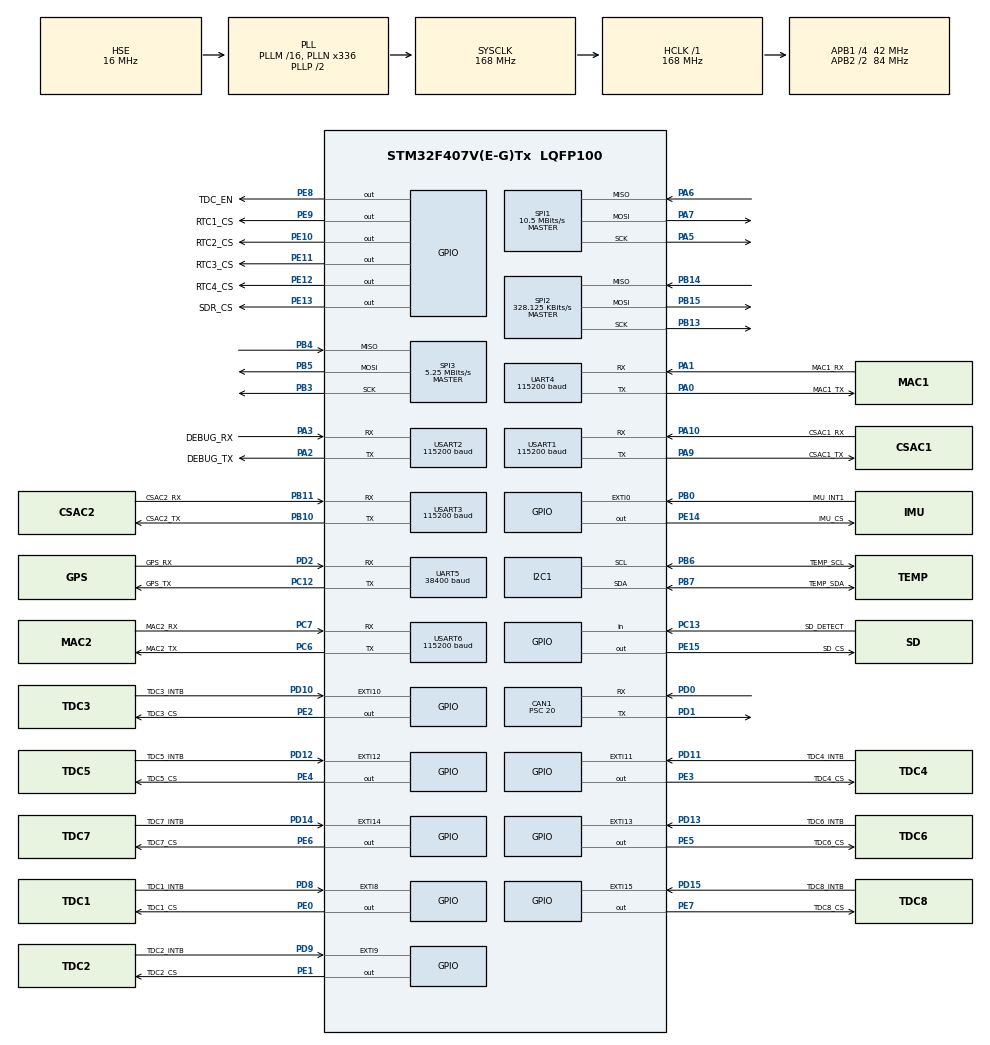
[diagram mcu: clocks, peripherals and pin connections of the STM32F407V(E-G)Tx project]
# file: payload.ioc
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CAN1.BS1=CAN_BS1_12TQ
CAN1.BS2=CAN_BS2_8TQ
CAN1.CalculateBaudRate=100000
CAN1.CalculateTimeBit=10000
CAN1.CalculateTimeQuantum=476.1904761904762
CAN1.Prescaler=20
CAN1.SJW=CAN_SJW_1TQ
Mcu.Family=STM32F4
Mcu.Name=STM32F407V(E-G)Tx
Mcu.Package=LQFP100
NVIC.EXTI0_IRQn=true\:0\:0\:false\:false\:true\:true\:true\:true
NVIC.EXTI15_10_IRQn=true\:0\:0\:false\:false\:true\:true\:true\:true
NVIC.EXTI9_5_IRQn=true\:0\:0\:false\:false\:true\:true\:true\:true
NVIC.PriorityGroup=NVIC_PRIORITYGROUP_4
PA0-WKUP.GPIO_Label=MAC1_TX
PA0-WKUP.Mode=Asynchronous
PA0-WKUP.Signal=UART4_TX
PA1.GPIO_Label=MAC1_RX
PA1.Mode=Asynchronous
PA1.Signal=UART4_RX
PA10.GPIO_Label=CSAC1_RX
PA10.Mode=Asynchronous
PA10.Signal=USART1_RX
PA13.Mode=Serial_Wire
PA13.Signal=SYS_JTMS-SWDIO
PA14.Mode=Serial_Wire
PA14.Signal=SYS_JTCK-SWCLK
PA2.GPIO_Label=DEBUG_TX
PA2.Mode=Asynchronous
PA2.Signal=USART2_TX
PA3.GPIO_Label=DEBUG_RX
PA3.Mode=Asynchronous
PA3.Signal=USART2_RX
PA5.Mode=Full_Duplex_Master
PA5.Signal=SPI1_SCK
PA6.Mode=Full_Duplex_Master
PA6.Signal=SPI1_MISO
PA7.Mode=Full_Duplex_Master
PA7.Signal=SPI1_MOSI
PA9.GPIO_Label=CSAC1_TX
PA9.Mode=Asynchronous
PA9.Signal=USART1_TX
PB0.GPIO_Label=IMU_INT1
PB0.GPIO_ModeDefaultEXTI=GPIO_MODE_IT_RISING
PB0.Signal=GPXTI0
PB10.GPIO_Label=CSAC2_TX
PB10.Mode=Asynchronous
PB10.Signal=USART3_TX
PB11.GPIO_Label=CSAC2_RX
PB11.Mode=Asynchronous
PB11.Signal=USART3_RX
PB13.Mode=Full_Duplex_Master
PB13.Signal=SPI2_SCK
PB14.Mode=Full_Duplex_Master
PB14.Signal=SPI2_MISO
PB15.Mode=Full_Duplex_Master
PB15.Signal=SPI2_MOSI
PB3.Mode=Full_Duplex_Master
PB3.Signal=SPI3_SCK
PB4.Mode=Full_Duplex_Master
PB4.Signal=SPI3_MISO
PB5.Mode=Full_Duplex_Master
PB5.Signal=SPI3_MOSI
PB6.GPIO_Label=TEMP_SCL
PB6.Mode=I2C
PB6.Signal=I2C1_SCL
PB7.GPIO_Label=TEMP_SDA
PB7.Mode=I2C
PB7.Signal=I2C1_SDA
PC12.GPIO_Label=GPS_TX
PC12.Mode=Asynchronous
PC12.Signal=UART5_TX
PC13-ANTI_TAMP.GPIO_Label=SD_DETECT
PC13-ANTI_TAMP.Signal=GPIO_Input
PC6.GPIO_Label=MAC2_TX
PC6.Mode=Asynchronous
PC6.Signal=USART6_TX
PC7.GPIO_Label=MAC2_RX
PC7.Mode=Asynchronous
PC7.Signal=USART6_RX
PD0.Mode=CAN_Activate
PD0.Signal=CAN1_RX
PD1.Mode=CAN_Activate
PD1.Signal=CAN1_TX
PD10.GPIO_Label=TDC3_INTB
PD10.GPIO_ModeDefaultEXTI=GPIO_MODE_IT_FALLING
PD10.Signal=GPXTI10
PD11.GPIO_Label=TDC4_INTB
PD11.GPIO_ModeDefaultEXTI=GPIO_MODE_IT_FALLING
PD11.Signal=GPXTI11
PD12.GPIO_Label=TDC5_INTB
PD12.GPIO_ModeDefaultEXTI=GPIO_MODE_IT_FALLING
PD12.Signal=GPXTI12
PD13.GPIO_Label=TDC6_INTB
PD13.GPIO_ModeDefaultEXTI=GPIO_MODE_IT_FALLING
PD13.Signal=GPXTI13
PD14.GPIO_Label=TDC7_INTB
PD14.GPIO_ModeDefaultEXTI=GPIO_MODE_IT_FALLING
PD14.Signal=GPXTI14
PD15.GPIO_Label=TDC8_INTB
PD15.GPIO_ModeDefaultEXTI=GPIO_MODE_IT_FALLING
PD15.Signal=GPXTI15
PD2.GPIO_Label=GPS_RX
PD2.Mode=Asynchronous
PD2.Signal=UART5_RX
PD8.GPIO_Label=TDC1_INTB
PD8.GPIO_ModeDefaultEXTI=GPIO_MODE_IT_FALLING
PD8.Signal=GPXTI8
PD9.GPIO_Label=TDC2_INTB
PD9.GPIO_ModeDefaultEXTI=GPIO_MODE_IT_FALLING
PD9.Signal=GPXTI9
PE0.GPIO_Label=TDC1_CS
PE0.PinState=GPIO_PIN_SET
PE0.Signal=GPIO_Output
PE1.GPIO_Label=TDC2_CS
PE1.PinState=GPIO_PIN_SET
PE1.Signal=GPIO_Output
PE10.GPIO_Label=RTC2_CS
PE10.PinState=GPIO_PIN_SET
PE10.Signal=GPIO_Output
PE11.GPIO_Label=RTC3_CS
PE11.PinState=GPIO_PIN_SET
PE11.Signal=GPIO_Output
PE12.GPIO_Label=RTC4_CS
PE12.PinState=GPIO_PIN_SET
PE12.Signal=GPIO_Output
PE13.GPIO_Label=SDR_CS
PE13.PinState=GPIO_PIN_SET
PE13.Signal=GPIO_Output
PE14.GPIO_Label=IMU_CS
PE14.PinState=GPIO_PIN_SET
PE14.Signal=GPIO_Output
PE15.GPIO_Label=SD_CS
PE15.PinState=GPIO_PIN_SET
PE15.Signal=GPIO_Output
PE2.GPIO_Label=TDC3_CS
PE2.PinState=GPIO_PIN_SET
PE2.Signal=GPIO_Output
PE3.GPIO_Label=TDC4_CS
PE3.PinState=GPIO_PIN_SET
PE3.Signal=GPIO_Output
PE4.GPIO_Label=TDC5_CS
PE4.PinState=GPIO_PIN_SET
PE4.Signal=GPIO_Output
PE5.GPIO_Label=TDC6_CS
PE5.PinState=GPIO_PIN_SET
PE5.Signal=GPIO_Output
PE6.GPIO_Label=TDC7_CS
PE6.PinState=GPIO_PIN_SET
PE6.Signal=GPIO_Output
PE7.GPIO_Label=TDC8_CS
PE7.PinState=GPIO_PIN_SET
PE7.Signal=GPIO_Output
PE8.GPIO_Label=TDC_EN
PE8.Signal=GPIO_Output
PE9.GPIO_Label=RTC1_CS
PE9.PinState=GPIO_PIN_SET
PE9.Signal=GPIO_Output
PH0-OSC_IN.Mode=HSE-External-Clock-Source
PH0-OSC_IN.Signal=RCC_OSC_IN
PH1-OSC_OUT.Mode=HSE-External-Clock-Source
PH1-OSC_OUT.Signal=RCC_OSC_OUT
ProjectManager.HeapSize=0x200
ProjectManager.StackSize=0x400
ProjectManager.TargetToolchain=STM32CubeIDE
RCC.AHBFreq_Value=168000000
RCC.APB1CLKDivider=RCC_HCLK_DIV4
RCC.APB1Freq_Value=42000000
RCC.APB1TimFreq_Value=84000000
RCC.APB2CLKDivider=RCC_HCLK_DIV2
RCC.APB2Freq_Value=84000000
RCC.APB2TimFreq_Value=168000000
RCC.CortexFreq_Value=168000000
RCC.FLatency=FLASH_LATENCY_5
RCC.HCLKFreq_Value=168000000
RCC.HSE_VALUE=16000000
RCC.HSI_VALUE=16000000
RCC.LSE_VALUE=32768
RCC.PLLM=16
RCC.PLLN=336
RCC.PLLQ=7
RCC.PLLSourceVirtual=RCC_PLLSOURCE_HSE
RCC.SYSCLKFreq_VALUE=168000000
RCC.SYSCLKSource=RCC_SYSCLKSOURCE_PLLCLK
RCC.VCOOutputFreq_Value=336000000
SPI1.BaudRatePrescaler=SPI_BAUDRATEPRESCALER_8
SPI1.CalculateBaudRate=10.5 MBits/s
SPI1.Direction=SPI_DIRECTION_2LINES
SPI1.Mode=SPI_MODE_MASTER
SPI1.VirtualType=VM_MASTER
SPI2.BaudRatePrescaler=SPI_BAUDRATEPRESCALER_128
SPI2.CalculateBaudRate=328.125 KBits/s
SPI2.Direction=SPI_DIRECTION_2LINES
SPI2.Mode=SPI_MODE_MASTER
SPI2.VirtualType=VM_MASTER
SPI3.BaudRatePrescaler=SPI_BAUDRATEPRESCALER_8
SPI3.CLKPhase=SPI_PHASE_2EDGE
SPI3.CLKPolarity=SPI_POLARITY_HIGH
SPI3.CalculateBaudRate=5.25 MBits/s
SPI3.Direction=SPI_DIRECTION_2LINES
SPI3.Mode=SPI_MODE_MASTER
SPI3.VirtualType=VM_MASTER
UART4.BaudRate=115200
UART4.VirtualMode=Asynchronous
UART5.BaudRate=38400
UART5.VirtualMode=Asynchronous
USART1.BaudRate=115200
USART1.VirtualMode=VM_ASYNC
USART2.BaudRate=115200
USART2.VirtualMode=VM_ASYNC
USART3.BaudRate=115200
USART3.VirtualMode=VM_ASYNC
USART6.BaudRate=115200
USART6.VirtualMode=VM_ASYNC
board=custom

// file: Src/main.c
/* USER CODE BEGIN Header */
/**
  ******************************************************************************
  * @file           : main.c
  * @brief          : Main program body
  ******************************************************************************
  * @attention
  *
  * Copyright (c) 2026 STMicroelectronics.
  * All rights reserved.
  *
  * This software is licensed under terms that can be found in the LICENSE file
  * in the root directory of this software component.
  * If no LICENSE file comes with this software, it is provided AS-IS.
  *
  ******************************************************************************
  */
/* USER CODE END Header */
#include "main.h"
#include "can.h"
#include "i2c.h"
#include "spi.h"
#include "usart.h"
#include "gpio.h"

/* USER CODE BEGIN Includes */
#include "MRT_main.h"
#include "MRT_setup.h"
/* USER CODE END Includes */

void SystemClock_Config(void);

int main(void)
{

  /* MCU Configuration--------------------------------------------------------*/

  /* Reset of all peripherals, Initializes the Flash interface and the Systick. */
  HAL_Init();

  /* Configure the system clock */
  SystemClock_Config();

  /* Initialize all configured peripherals */
  MX_GPIO_Init();
  MX_CAN1_Init();
  MX_I2C1_Init();
  MX_SPI1_Init();
  MX_SPI2_Init();
  MX_SPI3_Init();
  MX_UART4_Init();
  MX_UART5_Init();
  MX_USART1_UART_Init();
  MX_USART2_UART_Init();
  MX_USART3_UART_Init();
  MX_USART6_UART_Init();
  /* USER CODE BEGIN 2 */
  MRT_setup();
  MRT_main();
  /* USER CODE END 2 */

  /* Infinite loop */
  while (1)
  {

  }
}

void SystemClock_Config(void)
{
  RCC_OscInitTypeDef RCC_OscInitStruct = {0};
  RCC_ClkInitTypeDef RCC_ClkInitStruct = {0};

  /** Configure the main internal regulator output voltage
  */
  __HAL_RCC_PWR_CLK_ENABLE();
  __HAL_PWR_VOLTAGESCALING_CONFIG(PWR_REGULATOR_VOLTAGE_SCALE1);

  /** Initializes the RCC Oscillators according to the specified parameters
  * in the RCC_OscInitTypeDef structure.
  */
  RCC_OscInitStruct.OscillatorType = RCC_OSCILLATORTYPE_HSE;
  RCC_OscInitStruct.HSEState = RCC_HSE_BYPASS;
  RCC_OscInitStruct.PLL.PLLState = RCC_PLL_ON;
  RCC_OscInitStruct.PLL.PLLSource = RCC_PLLSOURCE_HSE;
  RCC_OscInitStruct.PLL.PLLM = 16;
  RCC_OscInitStruct.PLL.PLLN = 336;
  RCC_OscInitStruct.PLL.PLLP = RCC_PLLP_DIV2;
  RCC_OscInitStruct.PLL.PLLQ = 7;
  if (HAL_RCC_OscConfig(&RCC_OscInitStruct) != HAL_OK)
  {
    Error_Handler();
  }

  /** Initializes the CPU, AHB and APB buses clocks
  */
  RCC_ClkInitStruct.ClockType = RCC_CLOCKTYPE_HCLK|RCC_CLOCKTYPE_SYSCLK
                              |RCC_CLOCKTYPE_PCLK1|RCC_CLOCKTYPE_PCLK2;
  RCC_ClkInitStruct.SYSCLKSource = RCC_SYSCLKSOURCE_PLLCLK;
  RCC_ClkInitStruct.AHBCLKDivider = RCC_SYSCLK_DIV1;
  RCC_ClkInitStruct.APB1CLKDivider = RCC_HCLK_DIV4;
  RCC_ClkInitStruct.APB2CLKDivider = RCC_HCLK_DIV2;

  if (HAL_RCC_ClockConfig(&RCC_ClkInitStruct, FLASH_LATENCY_5) != HAL_OK)
  {
    Error_Handler();
  }
}

void Error_Handler(void)
{
  __disable_irq();
  while (1)
  {
  }
}
